VERSION "created by canmatrix"

NS_ :

BS_:

BU_: Host RT SYS MTR PWT DCDC EPS_C SEB HMI Any

BO_ 1 SAFETY_ESTOP_low: 0 Any

BO_ 288 SYS_THROTTLE_STS_low: 2 MTR
 SG_ speed_mmps : 7|16@0- (1,0) [-500|3000] "" RT,Host

BO_ 288 SYS_THROTTLE_STS_high: 2 MTR
 SG_ speed_mmps : 7|16@0- (1,0) [-500|3000] "" RT,Host

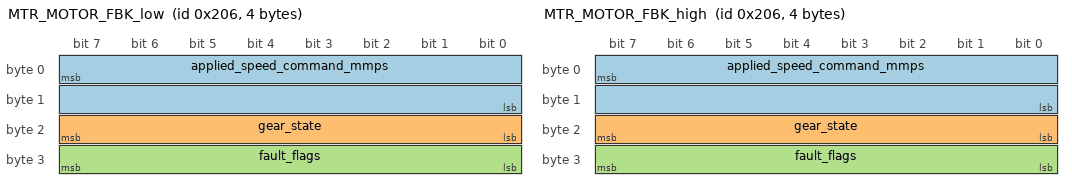
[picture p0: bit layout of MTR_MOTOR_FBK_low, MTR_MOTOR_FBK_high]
BO_ 518 MTR_MOTOR_FBK_low: 4 MTR
 SG_ applied_speed_command_mmps : 7|16@0- (1,0) [-500|3000] "" RT,SYS,Host
 SG_ gear_state : 23|8@0+ (1,0) [0|3] "" RT,SYS,Host
 SG_ fault_flags : 31|8@0+ (1,0) [0|255] "" RT,SYS,Host

BO_ 518 MTR_MOTOR_FBK_high: 4 MTR
 SG_ applied_speed_command_mmps : 7|16@0- (1,0) [-500|3000] "" RT,SYS,Host
 SG_ gear_state : 23|8@0+ (1,0) [0|3] "" RT,SYS,Host
 SG_ fault_flags : 31|8@0+ (1,0) [0|255] "" RT,SYS,Host

BO_ 516 RT_DRIVE_CMD_low: 5 RT
 SG_ motor_speed_mmps : 7|32@0- (1,0) [-500|3000] "" SYS,MTR
 SG_ gear : 39|8@0+ (1,0) [0|3] "" SYS,MTR

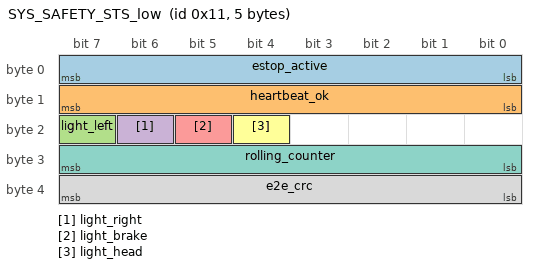
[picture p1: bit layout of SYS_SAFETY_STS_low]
BO_ 17 SYS_SAFETY_STS_low: 5 SYS
 SG_ estop_active : 7|8@0+ (1,0) [0|1] "" RT,MTR
 SG_ heartbeat_ok : 15|8@0+ (1,0) [0|1] "" RT,MTR
 SG_ light_left : 23|1@0+ (1,0) [0|1] "" RT,MTR
 SG_ light_right : 22|1@0+ (1,0) [0|1] "" RT,MTR
 SG_ light_brake : 21|1@0+ (1,0) [0|1] "" RT,MTR
 SG_ light_head : 20|1@0+ (1,0) [0|1] "" RT,MTR
 SG_ rolling_counter : 31|8@0+ (1,0) [0|255] "" RT,MTR
 SG_ e2e_crc : 39|8@0+ (1,0) [0|255] "" RT,MTR

BO_ 272 SYS_MODE_CMD_low: 2 SYS
 SG_ mode : 7|8@0+ (1,0) [0|1] "" RT,MTR
 SG_ rolling_counter : 15|8@0+ (1,0) [0|255] "" RT,MTR

BO_ 275 SYS_PWR_CMD_low: 2 SYS
 SG_ power_state : 7|8@0+ (1,0) [0|1] "" MTR
 SG_ rolling_counter : 15|8@0+ (1,0) [0|255] "" MTR

BA_DEF_ BO_ "GenMsgCycleTime" INT 0 65535;

BA_ "GenMsgCycleTime" BO_ 288 10;
BA_ "GenMsgCycleTime" BO_ 288 10;
BA_ "GenMsgCycleTime" BO_ 518 20;
BA_ "GenMsgCycleTime" BO_ 518 20;
BA_ "GenMsgCycleTime" BO_ 516 10;
BA_ "GenMsgCycleTime" BO_ 17 200;
BA_ "GenMsgCycleTime" BO_ 272 100;
BA_ "GenMsgCycleTime" BO_ 275 100;

VAL_ 516 gear 0 "N" 1 "D" 2 "S" 3 "R";
VAL_ 272 mode 0 "MANUAL" 1 "AUTO";
VAL_ 275 power_state 0 "OFF" 1 "ON";
